# MSP430FR5739 register map
File version: 1.1
CPU: msp430
Registers are 16-bit, access not given, reset 0x0 unless marked. A register's access mark holds for its fields unless they carry their own. Offsets are from the block's base; lines under a group give offsets from that group; [hi:lo] are bit positions; {n}, {i} and the like mark numbered series; 'fields as' and 'values as' point back to an identical list; <NAME> marks a mode.

## Memory map
0x00000000 ADC10_B size 0xA
0x00000000 CS__Clock_System size 0xA
0x00000000 Comparator_D size 0xA
0x00000000 CRC16 size 0xA
0x00000000 DMA size 0xA
0x00000000 FRAM size 0xA
0x00000000 MPU size 0xA
0x00000000 MPY_16__Multiplier__16_Bit_Mode size 0xA
0x00000000 MPY_32__Multiplier__32_Bit_Mode size 0xA
0x00000000 PMM__Power_Management_System size 0xA
0x00000000 Port_A size 0xA
0x00000000 Port_1_2 size 0xA
0x00000000 Port_B size 0xA
0x00000000 Port_3_4 size 0xA
0x00000000 Port_J size 0xA
0x00000000 Shared_Reference size 0xA
0x00000000 RTC_B__Real_Time_Clock size 0xA
0x00000000 SFR__Special_Function_Registers size 0xA
0x00000000 SYS__System_Module size 0xA
0x00000000 Timer0_A3 size 0xA
0x00000000 Timer1_A3 size 0xA
0x00000000 Timer0_B3 size 0xA
0x00000000 Timer1_B3 size 0xA
0x00000000 Timer2_B3 size 0xA
0x00000000 USCI_A0__UART_Mode size 0xA
0x00000000 USCI_A0__SPI_Mode size 0xA
0x00000000 USCI_B0__SPI_Mode size 0xA
0x00000000 USCI_B0__I2C_Mode size 0xA
0x00000000 USCI_A1__UART_Mode size 0xA
0x00000000 USCI_A1__SPI_Mode size 0xA
0x00000000 Watchdog_Timer size 0xA

## ADC10_B
Base 0x00000000
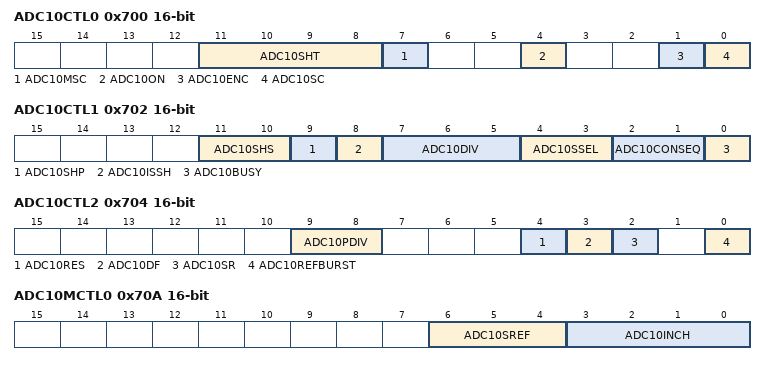
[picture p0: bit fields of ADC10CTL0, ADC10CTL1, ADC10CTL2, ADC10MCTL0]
0x700 ADC10CTL0 — ADC10 Control 0
  [11:8] ADC10SHT — [11:8] ADC10 Sample Hold Select Bit: 0
    {v}=ADC10 Sample Hold Select {v} (v=0..15)
  [7] ADC10MSC — [7:7] ADC10 Multiple SampleConversion
  [4] ADC10ON — [4:4] ADC10 On/enable
  [1] ADC10ENC — [1:1] ADC10 Enable Conversion
  [0] ADC10SC — [0:0] ADC10 Start Conversion
0x702 ADC10CTL1 — ADC10 Control 1
  [11:10] ADC10SHS — [11:10] ADC10 Sample/Hold Source 0
    {v}=ADC10 Sample/Hold Source: {v} (v=0..3)
  [9] ADC10SHP — [9:9] ADC10 Sample/Hold Pulse Mode
  [8] ADC10ISSH — [8:8] ADC10 Invert Sample Hold Signal
  [7:5] ADC10DIV — [7:5] ADC10 Clock Divider Select 0
    {v}=ADC10 Clock Divider Select: {v} (v=0..7)
  [4:3] ADC10SSEL — [4:3] ADC10 Clock Source Select 0
    {v}=ADC10 Clock Source Select: {v} (v=0..3)
  [2:1] ADC10CONSEQ — [2:1] ADC10 Conversion Sequence Select 0
    {v}=ADC10 Conversion Sequence Select: {v} (v=0..3)
  [0] ADC10BUSY — [0:0] ADC10 Busy
0x704 ADC10CTL2 — ADC10 Control 2
  [9:8] ADC10PDIV — [9:8] ADC10 predivider Bit: 0
    0=ADC10 predivider /1; 1=ADC10 predivider /2; 2=ADC10 predivider /64; 3=ADC10 predivider reserved
  [4] ADC10RES — [4:4] ADC10 Resolution Bit
  [3] ADC10DF — [3:3] ADC10 Data Format
  [2] ADC10SR — [2:2] ADC10 Sampling Rate
  [0] ADC10REFBURST — [0:0] ADC10 Reference Burst
0x706 ADC10LO — ADC10 Window Comparator High Threshold
0x708 ADC10HI — ADC10 Window Comparator High Threshold
0x70A ADC10MCTL0 — ADC10 Memory Control 0
  [6:4] ADC10SREF — [6:4] ADC10 Select Reference Bit 0
    {v}=ADC10 Select Reference {v} (v=0..7)
  [3:0] ADC10INCH — [3:0] ADC10 Input Channel Select Bit 0
    {v}=ADC10 Input Channel {v} (v=0..15)
0x712 ADC10MEM0 — ADC10 Conversion Memory 0
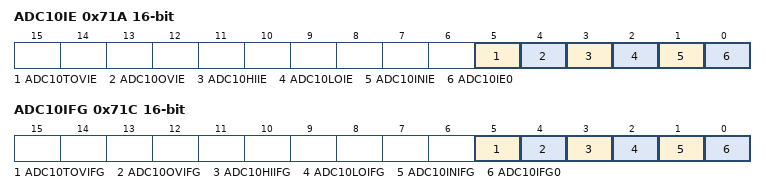
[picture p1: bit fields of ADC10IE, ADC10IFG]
0x71A ADC10IE — ADC10 Interrupt Enable
  [5] ADC10TOVIE — [5:5] ADC10_A conversion-time-overflow Interrupt enable
  [4] ADC10OVIE — [4:4] ADC10_A ADC10MEM overflow Interrupt enable
  [3] ADC10HIIE — [3:3] ADC10_A Interrupt enable for upper threshold of the Window comparator
  [2] ADC10LOIE — [2:2] ADC10_A Interrupt enable for lower threshold of the Window comparator
  [1] ADC10INIE — [1:1] ADC10_A Interrupt enable for the inside of window of the Window comparator
  [0] ADC10IE0 — [0:0] ADC10_A Interrupt enable
0x71C ADC10IFG — ADC10 Interrupt Flag
  [5] ADC10TOVIFG — [5:5] ADC10_A conversion-time-overflow Interrupt Flag
  [4] ADC10OVIFG — [4:4] ADC10_A ADC10MEM overflow Interrupt Flag
  [3] ADC10HIIFG — [3:3] ADC10_A Interrupt Flag for upper threshold of the Window comparator
  [2] ADC10LOIFG — [2:2] ADC10_A Interrupt Flag for lower threshold of the Window comparator
  [1] ADC10INIFG — [1:1] ADC10_A Interrupt Flag for the inside of window of the Window comparator
  [0] ADC10IFG0 — [0:0] ADC10_A Interrupt Flag
0x71E ADC10IV — ADC10 Interrupt Vector Word
